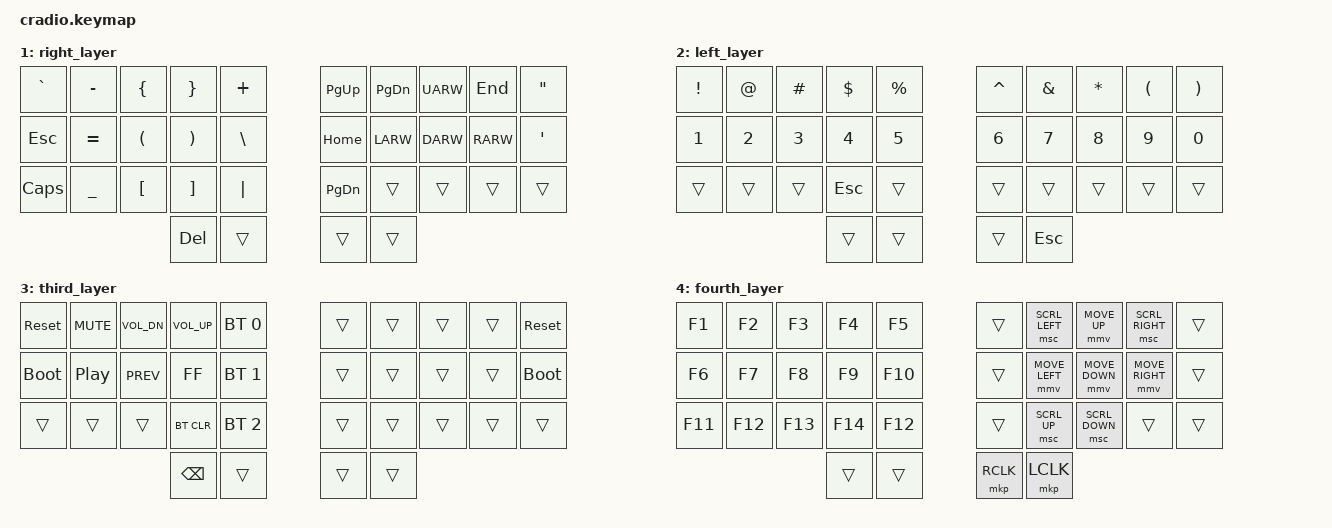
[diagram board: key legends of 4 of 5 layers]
// Copyright (c) 2022 The ZMK Contributors
// SPDX-License-Identifier: MIT

#include <behaviors.dtsi>
#include <dt-bindings/zmk/keys.h>
#include <dt-bindings/zmk/bt.h>
#include <dt-bindings/zmk/pointing.h>

// Home row mods macro
#define HRML(k1,k2,k3,k4) &ht LSHFT k1  &ht LALT k2  &ht LGUI k3  &ht LCTRL k4
#define HRMR(k1,k2,k3,k4) &ht RCTRL k1  &ht RGUI k2  &ht RALT k3  &ht RSHFT k4

/ {
    behaviors {
        ht: hold_tap {
            label = "hold_tap";
            compatible = "zmk,behavior-hold-tap";
            #binding-cells = <2>;
            flavor = "balanced";
            tapping-term-ms = <200>;
            quick-tap-ms = <175>;
            global-quick-tap;
            bindings = <&kp>, <&kp>;
        };
    };

    conditional_layers {
        compatible = "zmk,conditional-layers";
//        tri_layer {
//            if-layers = <1 2>;
//            then-layer = <3>;
//        };
    };

    keymap {
        compatible = "zmk,keymap";
        default_layer {
            bindings = <
        //╭──────────┬──────────┬──────────┬──────────┬──────────╮   ╭──────────┬──────────┬──────────┬──────────┬──────────╮
        //│  Q       │  W       │  E       │  R       │  T       │   │  Y       │  U       │  I       │  O       │  P       │
            &kp Q      &kp W      &kp E      &kp R      &kp T          &kp Y      &kp U      &kp I      &kp O      &kp P
        //├──────────┼──────────┼──────────┼──────────┼──────────┤   ├──────────┼──────────┼──────────┼──────────┼──────────┤
        //│  A       │  S       │  D       │  F       │  G       │   │  H       │  J       │  K       │  L       │  ;       │
            HRML(A,        S,         D,         F)     &kp G          &kp H      HRMR(J,        K,         L,      SEMI)
        //├──────────┼──────────┼──────────┼──────────┼──────────┤   ├──────────┼──────────┼──────────┼──────────┼──────────┤
        //│  Z       │  X       │  C       │  V       │  B       │   │  N       │  M       │ , <      │ . >      │ / ?      │
            &kp Z      &kp X      &kp C      &kp V      &kp B          &kp N      &kp M      &kp COMMA  &kp DOT    &lt 4 FSLH
        //╰──────────┴──────────┴──────────┼──────────┼──────────┤   ├──────────┼──────────┼──────────┴──────────┴──────────╯
                                            &lt 2 BSPC  &lt 3 TAB      &kp ENTER  &lt 1 SPACE
        //                                 ╰──────────┴──────────╯   ╰──────────┴──────────╯
            >;
        };

        right_layer {
            bindings = <
        //╭──────────┬──────────┬──────────┬──────────┬──────────╮   ╭──────────┬──────────┬──────────┬──────────┬──────────╮
        //│ `        │  -       │  {       │  }       │  +       │   │ PAGE UP  │ PAGE DN  │ UP       │ END      │  "       │
            &kp GRAVE &kp MINUS  &kp LBRC   &kp RBRC   &kp PLUS       &kp PG_UP  &kp PG_DN  &kp UARW   &kp END    &kp DQT 
        //├──────────┼──────────┼──────────┼──────────┼──────────┤   ├──────────┼──────────┼──────────┼──────────┼──────────┤
        //│ ESC      │  =       │  (       │  )       │  \       │   │ HOME     │ LEFT     │ DOWN     │ RIGHT    │  '       │
            &kp ESC    &kp EQUAL  &kp LPAR   &kp RPAR   &kp BSLH       &kp HOME   &kp LARW   &kp DARW   &kp RARW   &kp SQT
        //├──────────┼──────────┼──────────┼──────────┼──────────┤   ├──────────┼──────────┼──────────┼──────────┼──────────┤
        //│ CAPS LCK │  _       │  [       │  ]       │  |       │   │ PAGE DN  │          │          │          │          │
            &kp CAPS   &kp UNDER  &kp LBKT   &kp RBKT   &kp PIPE       &kp PG_DN  &trans     &trans     &trans     &trans
        //╰──────────┴──────────┴──────────┼──────────┼──────────┤   ├──────────┼──────────┼──────────┴──────────┴──────────╯
                                             &kp DEL     &trans        &trans     &trans
        //                                 ╰──────────┴──────────╯   ╰──────────┴──────────╯
            >;
        };

        left_layer {
            bindings = <
        //╭──────────┬──────────┬──────────┬──────────┬──────────╮   ╭──────────┬──────────┬──────────┬──────────┬──────────╮
        //│  !       │  @       │  #       │  $       │  %       │   │  ^       │  &       │  *       │  (       │  )       │
            &kp EXCL   &kp AT     &kp HASH   &kp DLLR   &kp PRCNT      &kp CARET  &kp AMPS   &kp ASTRK  &kp LPAR   &kp RPAR
        //├──────────┼──────────┼──────────┼──────────┼──────────┤   ├──────────┼──────────┼──────────┼──────────┼──────────┤
        //│  1       │  2       │  3       │  4       │  5       │   │  6       │  7       │  8       │  9       │  0       │
            &kp N1     &kp N2     &kp N3     &kp N4     &kp N5         &kp N6     &kp N7     &kp N8     &kp N9     &kp N0
        //├──────────┼──────────┼──────────┼──────────┼──────────┤   ├──────────┼──────────┼──────────┼──────────┼──────────┤
        //│          │          │          │ ESC      │          │   │          │          │          │          │          │
            &trans     &trans     &trans     &kp ESC    &trans         &trans     &trans     &trans     &trans     &trans
        //╰──────────┴──────────┴──────────┼──────────┼──────────┤   ├──────────┼──────────┼──────────┴──────────┴──────────╯
                                             &trans     &trans         &trans     &kp ESC
        //                                 ╰──────────┴──────────╯   ╰──────────┴──────────╯
            >;
        };

        third_layer {
            bindings = <
        //╭──────────┬──────────┬──────────┬──────────┬──────────╮   ╭──────────┬──────────┬──────────┬──────────┬──────────╮
        //│ RESET    │ MUTE     │  VOL DN  │  VOL UP  │PROFILE 0 │   │          │          │          │          │  RESET   │
            &sys_reset   &kp C_MUTE &kp C_VOL_DN &kp C_VOL_UP &bt BT_SEL 0 &trans  &trans     &trans    &trans      &sys_reset
        //├──────────┼──────────┼──────────┼──────────┼──────────┤   ├──────────┼──────────┼──────────┼──────────┼──────────┤
        //│BOOTLOADER│ PLAY/PSE │ PREV     │ FF       │PROFILE 1 │   │          │          │          │          │BOOTLOADER│
          &bootloader  &kp C_PP   &kp C_PREV &kp C_FF  &bt BT_SEL 1    &trans     &trans     &trans     &trans    &bootloader
        //├──────────┼──────────┼──────────┼──────────┼──────────┤   ├──────────┼──────────┼──────────┼──────────┼──────────┤
        //│          │          │          │ CLEAR BT │PROFILE 2 │   │          │          │          │          │          │
            &trans     &trans     &trans    &bt BT_CLR &bt BT_SEL 2    &trans     &trans     &trans     &trans     &trans
        //╰──────────┴──────────┴──────────┼──────────┼──────────┤   ├──────────┼──────────┼──────────┴──────────┴──────────╯
                                             &kp BSPC   &trans         &trans     &trans
        //                                 ╰──────────┴──────────╯   ╰──────────┴──────────╯
            >;
        };

        fourth_layer {
            bindings = <
        //╭──────────┬──────────┬──────────┬──────────┬──────────╮   ╭──────────┬──────────────┬──────────────┬───────────────┬──────────╮
        //│          │          │          │          │          │   │          │              │              │               │          |
            &kp F1     &kp F2     &kp F3     &kp F4     &kp F5        &trans     &msc SCRL_LEFT  &mmv MOVE_UP  &msc SCRL_RIGHT   &trans
        //├──────────┼──────────┼──────────┼──────────┼──────────┤   ├──────────┼──────────────┼──────────────┼───────────────┼──────────┤
        //│          │          │          │          │          │   │          │              │              │               │          │
            &kp F6     &kp F7     &kp F8     &kp F9     &kp F10        &trans    &mmv MOVE_LEFT &mmv MOVE_DOWN &mmv MOVE_RIGHT   &trans 
        //├──────────┼──────────┼──────────┼──────────┼──────────┤   ├──────────┼──────────────┼──────────────┼───────────────┼──────────┤
        //│          │          │          │          │          │   │          │              │              │               │          │
            &kp F11    &kp F12    &kp F13    &kp F14    &kp F12        &trans    &msc SCRL_UP   &msc SCRL_DOWN &trans           &trans
        //╰──────────┴──────────┴──────────┼──────────┼──────────┤   ├──────────┼──────────────┼──────────────┴───────────────┴──────────╯
                                             &trans      &trans         &mkp RCLK  &mkp LCLK
        //                                 ╰──────────┴──────────╯   ╰──────────┴──────────────╯
            >;
        };
    };
};
